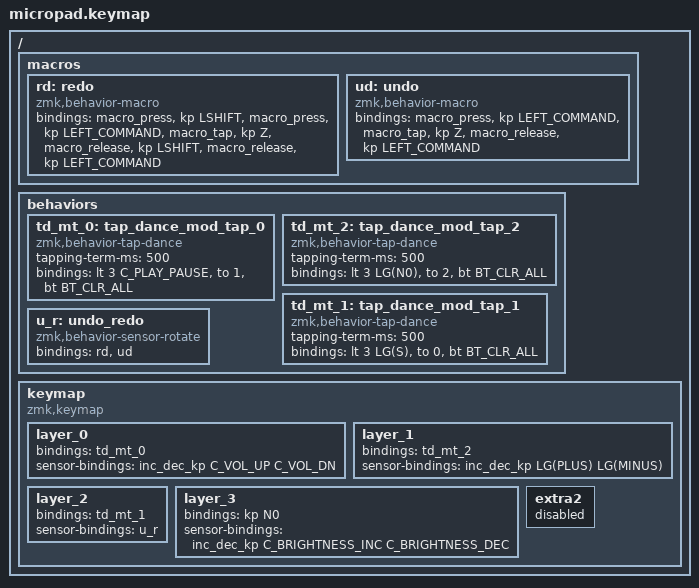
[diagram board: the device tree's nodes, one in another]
#include <behaviors.dtsi>
#include <dt-bindings/zmk/bt.h>
#include <dt-bindings/zmk/keys.h>

/ {
    macros {
        rd: redo {
            compatible = "zmk,behavior-macro";
            #binding-cells = <0>;
            bindings
                = <&macro_press &kp LSHIFT>
                , <&macro_press &kp LEFT_COMMAND>
                , <&macro_tap &kp Z>
                , <&macro_release &kp LSHIFT>
                , <&macro_release &kp LEFT_COMMAND>
                ;
        };
        ud: undo {
            compatible = "zmk,behavior-macro";
            #binding-cells = <0>;
            bindings
                = <&macro_press &kp LEFT_COMMAND>
                , <&macro_tap &kp Z>
                , <&macro_release &kp LEFT_COMMAND>
                ;
        };
    };
    behaviors {
        td_mt_0: tap_dance_mod_tap_0 {
            compatible = "zmk,behavior-tap-dance";
            #binding-cells = <0>;
            tapping-term-ms = <500>;
            bindings = <&lt 3 C_PLAY_PAUSE>, <&to 1>, <&bt BT_CLR_ALL>;
        };
        td_mt_2: tap_dance_mod_tap_2 {
            compatible = "zmk,behavior-tap-dance";
            #binding-cells = <0>;
            tapping-term-ms = <500>;
            bindings = <&lt 3 LG(N0)>, <&to 2>, <&bt BT_CLR_ALL>;
        };
        td_mt_1: tap_dance_mod_tap_1 {
            compatible = "zmk,behavior-tap-dance";
            #binding-cells = <0>;
            tapping-term-ms = <500>;
            bindings = <&lt 3 LG(S)>, <&to 0>, <&bt BT_CLR_ALL>;
        };
        u_r: undo_redo {
            compatible = "zmk,behavior-sensor-rotate";
            #sensor-binding-cells = <0>;
            bindings = <&rd>, <&ud>;
        };
    };
    keymap {
        compatible = "zmk,keymap";
        layer_0 {
            bindings = <&td_mt_0>;
            sensor-bindings = <&inc_dec_kp C_VOL_UP C_VOL_DN>;
        };
        layer_1 {
            bindings = <&td_mt_2>;
            sensor-bindings = <&inc_dec_kp LG(PLUS) LG(MINUS)>;
        };
        layer_2 {
            bindings = <&td_mt_1>;
            sensor-bindings = <&u_r>;
        };
        layer_3 {
            bindings = <&kp N0>;
            sensor-bindings = <&inc_dec_kp C_BRIGHTNESS_INC C_BRIGHTNESS_DEC>;
        };
        extra2 {
            status = "reserved";
        };
    };
};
